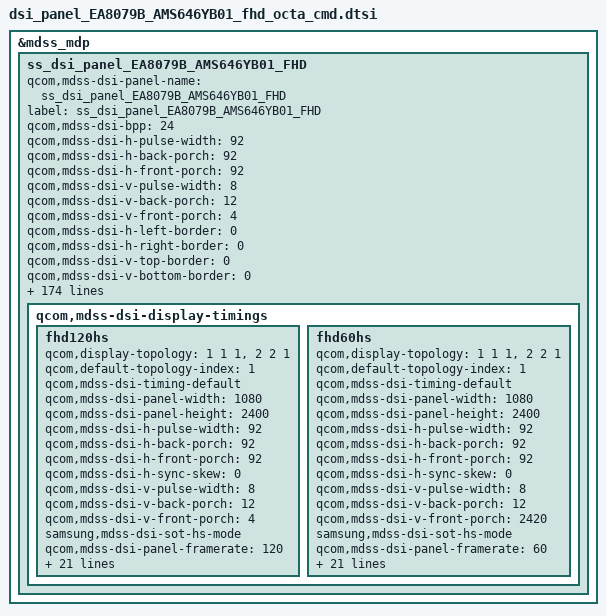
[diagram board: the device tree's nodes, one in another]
/* Copyright (c) 2020, Samsung Electronics Corporation. All rights reserved.
 *
 * This program is free software; you can redistribute it and/or modify
 * it under the terms of the GNU General Public License version 2 and
 * only version 2 as published by the Free Software Foundation.
 *
 * This program is distributed in the hope that it will be useful,
 * but WITHOUT ANY WARRANTY; without even the implied warranty of
 * MERCHANTABILITY or FITNESS FOR A PARTICULAR PURPOSE.  See the
 * GNU General Public License for more details.
 */

&mdss_mdp {
	ss_dsi_panel_EA8079B_AMS646YB01_FHD: ss_dsi_panel_EA8079B_AMS646YB01_FHD {
		qcom,mdss-dsi-panel-name = "ss_dsi_panel_EA8079B_AMS646YB01_FHD";
		label = "ss_dsi_panel_EA8079B_AMS646YB01_FHD";

		qcom,mdss-dsi-bpp = <24>;

		qcom,mdss-dsi-h-pulse-width = <92>;
		qcom,mdss-dsi-h-back-porch = <92>;
		qcom,mdss-dsi-h-front-porch = <92>;
		qcom,mdss-dsi-v-pulse-width = <8>;
		qcom,mdss-dsi-v-back-porch = <12>;
		qcom,mdss-dsi-v-front-porch = <4>;

		qcom,mdss-dsi-h-left-border = <0>;
		qcom,mdss-dsi-h-right-border = <0>;
		qcom,mdss-dsi-v-top-border = <0>;
		qcom,mdss-dsi-v-bottom-border = <0>;

		qcom,mdss-dsi-panel-phy-timings = [00 25 0A 0A 27 24 0A 0A 09 02 04 00 1F 1A];	// 1110 Mbps

		qcom,mdss-dsi-underflow-color = <0xFF>;
		qcom,mdss-dsi-border-color = <0>;

		qcom,mdss-dsi-bl-pmic-control-type = "bl_ctrl_dcs";

		qcom,mdss-dsi-bl-min-level = <1>;
		qcom,mdss-dsi-bl-max-level = <486>;
		qcom,mdss-brightness-max-level = <486>;
		qcom,mdss-brightness-default-level = <255>;
		qcom,mdss-dsi-interleave-mode = <0>;
		qcom,mdss-dsi-panel-type = "dsi_cmd_mode";

		qcom,mdss-dsi-te-check-enable;
		qcom,mdss-dsi-te-using-te-pin;
		qcom,mdss-dsi-te-pin-select = <1>;

		/*qcom,dynamic-mode-switch-enabled;*/
		/*qcom,dynamic-mode-switch-type = "dynamic-resolution-switch-immediate";*/

		qcom,mdss-dsi-te-dcs-command = <1>;
		qcom,mdss-dsi-wr-mem-start = <0x2C>;
		qcom,mdss-dsi-wr-mem-continue = <0x3C>;

		qcom,mdss-dsi-pixel-packing = "loose";

		qcom,mdss-dsi-virtual-channel-id = <0>;
		qcom,mdss-dsi-color-order = "rgb_swap_rgb";
		qcom,mdss-dsi-lane-0-state;
		qcom,mdss-dsi-lane-1-state;
		qcom,mdss-dsi-lane-2-state;
		qcom,mdss-dsi-lane-3-state;
		//qcom,mdss-dsi-lane-map = "lane_map_0123";

		qcom,mdss-dsi-t-clk-pre = <0x1F>;
		qcom,mdss-dsi-t-clk-post = <0x1A>;

		qcom,mdss-dsi-stream = <0>;
		qcom,mdss-dsi-mdp-trigger = "none";
		qcom,mdss-dsi-dma-trigger = "trigger_sw";

		qcom,mdss-pan-physical-width-dimension = <67>;	/*  67.28 : round-off */
		qcom,mdss-pan-physical-height-dimension = <150>;/* 149.52 : round-off */

		qcom,mdss-dsi-reset-sequence = <0 10>, <1 15>;

		qcom,mdss-dsi-lp11-init;
		/*qcom,mdss-dsi-init-delay-us = <1000>;*/

		qcom,mdss-dsi-rx-eot-ignore;
		qcom,mdss-dsi-tx-eot-append;

		/* HDR Setting */
		qcom,mdss-dsi-panel-hdr-enabled;
		qcom,mdss-dsi-panel-hdr-color-primaries = <15635 16450 34000 16000 13250 34500 7500 3000>;
		qcom,mdss-dsi-panel-peak-brightness = <5400000>;
		qcom,mdss-dsi-panel-average-brightness = <2000000>;
		qcom,mdss-dsi-panel-blackness-level = <2000>;

		qcom,ulps-enabled;
		/* qcom,suspend-ulps-enabled; */
		qcom,esd-check-enabled;
		qcom,mdss-dsi-panel-status-check-mode ="irq_check";
		qcom,mdss-dsi-panel-status-irq-trigger1 = "falling";
		/*qcom,mdss-dsi-panel-status-read-length;*/
		/*qcom,mdss-dsi-panel-status-value;*/
		/*qcom,mdss-dsi-panel-status-irq-trigger2 = "falling";*/

		/* *************************************************************
		 * Below  parameters are samsung dependent thigs
		 * *************************************************************
		 */
		samsung,panel-vendor = "SDC";
		samsung,disp-model = "AMS646YB01";
		samsung,panel-lpm-enable;
		samsung,support_gamma_mode2;
		//samsung,elvss_interpolation_temperature = <(-15)>;
		samsung,support_factory_panel_swap;
		samsung,support_gpara;
		samsung,pll_ssc_disabled;

		/* *************************************************************
		 *  Tx
		 * *************************************************************
		 */
		samsung,level0_key_enable_tx_cmds_revA	= [29 01 00 00 00 00 03 9F A5 A5]; /* PASSWD0 */
		samsung,level0_key_disable_tx_cmds_revA	= [29 01 00 00 00 00 03 9F 5A 5A]; /* PASSWD0 */
		samsung,level1_key_enable_tx_cmds_revA	= [29 01 00 00 00 00 03 F0 5A 5A]; /* PASSWD1 */
		samsung,level1_key_disable_tx_cmds_revA	= [29 01 00 00 00 00 03 F0 A5 A5]; /* PASSWD1 */
		samsung,level2_key_enable_tx_cmds_revA	= [29 01 00 00 00 00 03 FC 5A 5A];
		samsung,level2_key_disable_tx_cmds_revA	= [29 01 00 00 00 00 03 FC A5 A5];

		/* BRIGHTNESS_MAX_PACKET = 50 */
		samsung,brightness_tx_cmds_revA = [
			39 01 00 00 00 00 01 00
			39 01 00 00 00 00 01 00
			39 01 00 00 00 00 01 00
			39 01 00 00 00 00 01 00
			39 01 00 00 00 00 01 00
			39 01 00 00 00 00 01 00
			39 01 00 00 00 00 01 00
			39 01 00 00 00 00 01 00
			39 01 00 00 00 00 01 00
			39 01 00 00 00 00 01 00
			39 01 00 00 00 00 01 00
			39 01 00 00 00 00 01 00
			39 01 00 00 00 00 01 00
			39 01 00 00 00 00 01 00
			39 01 00 00 00 00 01 00
			39 01 00 00 00 00 01 00
			39 01 00 00 00 00 01 00
			39 01 00 00 00 00 01 00
			39 01 00 00 00 00 01 00
			39 01 00 00 00 00 01 00
			39 01 00 00 00 00 01 00
			39 01 00 00 00 00 01 00
			39 01 00 00 00 00 01 00
			39 01 00 00 00 00 01 00
			39 01 00 00 00 00 01 00
			39 01 00 00 00 00 01 00
			39 01 00 00 00 00 01 00
			39 01 00 00 00 00 01 00
			39 01 00 00 00 00 01 00
			39 01 00 00 00 00 01 00
			39 01 00 00 00 00 01 00
			39 01 00 00 00 00 01 00
			39 01 00 00 00 00 01 00
			39 01 00 00 00 00 01 00
			39 01 00 00 00 00 01 00
			39 01 00 00 00 00 01 00
			39 01 00 00 00 00 01 00
			39 01 00 00 00 00 01 00
			39 01 00 00 00 00 01 00
			39 01 00 00 00 00 01 00
			39 01 00 00 00 00 01 00
			39 01 00 00 00 00 01 00
			39 01 00 00 00 00 01 00
			39 01 00 00 00 00 01 00
			39 01 00 00 00 00 01 00
			39 01 00 00 00 00 01 00
			39 01 00 00 00 00 01 00
			39 01 00 00 00 00 01 00
			39 01 00 00 00 00 01 00
			39 01 00 00 00 00 01 00
		];

		//samsung,mdnie_tx_cmds_revA = [
		//	39 01 00 00 00 00 00 00 00
		//];

		samsung,packet_size_tx_cmds_revA = [
			37 01 00 00 00 00 02 07 00
		];

		/* use poinging gpara (long write) */
		samsung,reg_read_pos_tx_cmds_revA = [
			29 00 00 00 00 00 03 B0 00 00
		];

		samsung,display_on_tx_cmds_revA = [05 01 00 00 00 00 02 29 00];
		samsung,display_off_tx_cmds_revA = [05 01 00 00 00 00 02 28 00];

		/* *************************************************************
		 *  Rx (Module Information READ)
		 * *************************************************************
		 */
		samsung,mdnie_read_rx_cmds_revA		= [06 01 00 00 00 00 01 EA 04 03]; /* White color position EA 4th ~ 7th */
		samsung,manufacture_date_rx_cmds_revA	= [06 01 00 00 00 00 01 EA 07 07]; /* manufacture data EA 8th ~ 14th*/
		samsung,octa_id_rx_cmds_revA		= [06 01 00 00 00 00 01 EA 14 0E]; /* ID (4bytes) + Cell ID(16bytes) */
		samsung,cell_id_rx_cmds_revA		= [06 01 00 00 00 00 01 EA 07 07]; /* Cell ID 16bytes EA 8th ~ 14th*/
		samsung,ddi_id_rx_cmds_revA		= [06 01 00 00 00 00 01 D1 06 60]; /* CHIP ID : read D1 96~101th */
		samsung,ddi_id_length = <6>;

		samsung,manufacture_id0_rx_cmds_revA	= [06 01 00 00 00 00 01 da 01 00];
		samsung,manufacture_id1_rx_cmds_revA	= [06 01 00 00 00 00 01 db 01 00];
		samsung,manufacture_id2_rx_cmds_revA	= [06 01 00 00 00 00 01 dc 01 00];

		samsung,ldi_debug0_rx_cmds_revA		= [06 01 00 00 00 00 01 0A 01 00]; /* rddpm */
		//samsung,ldi_debug1_rx_cmds_revA		= [06 01 00 00 00 00 01 0E 01 00]; /* no operation */
		samsung,ldi_debug2_rx_cmds_revA		= [06 01 00 00 00 00 01 0E 01 00]; /* errfg */
		samsung,ldi_debug3_rx_cmds_revA		= [06 01 00 00 00 00 01 0E 01 00]; /* rddsm*/
		samsung,ldi_debug4_rx_cmds_revA		= [06 01 00 00 00 00 01 05 01 00]; /* dsierr */
		//samsung,ldi_debug5_rx_cmds_revA		= [06 01 00 00 00 00 01 0F 01 00]; /* self_diag*/

		/* 255 bytes, its ddi max size is 512, and sw limit is ff = 255... */
		//samsung,ldi_debug_logbuf_rx_cmds_revA	= [06 01 00 00 00 00 01 9C FF 00];

		samsung,mtp_read_sysfs_rx_cmds_revA	= [06 01 00 00 00 00 01 00 00 00];

		samsung,mtp_write_sysfs_tx_cmds_revA	= [
			29 00 00 00 00 00 3D 00
						00 00 00 00 00 00 00 00 00 00
						00 00 00 00 00 00 00 00 00 00
						00 00 00 00 00 00 00 00 00 00
						00 00 00 00 00 00 00 00 00 00
						00 00 00 00 00 00 00 00 00 00
						00 00 00 00 00 00 00 00 00 00
		];

		samsung,smart_dimming_mtp_rx_cmds_revA	= [06 01 00 00 00 00 01 B9 DE 00];

		/* *************************************************************
		 * ACL command list and mappings
		 * **************************************************************
		 */
		samsung,acl_on_tx_cmds_revA = [
			/* 32 frame AVG ACL ON, Start 50%, ACL 15%, 32Frame AVG */
			29 01 00 00 00 00 02 55 02	/* 8%(0x01), 15%(0x02) */
		];

		samsung,acl_off_tx_cmds_revA = [
			/* 16 Frame AVG ACL OFF, Start Point 60%, ACL 0%*/
			29 01 00 00 00 00 02 55 00	/* ACL OFF */
		];

		samsung,elvss_rx_cmds_revA = [ 06 01 00 00 00 00 01 B7 02 07];	/* read B7 8th, 9th para */

		/* *************************************************************
		 * Dynamic MIPI Clock
		 * **************************************************************
		 */
		samsung,support_dynamic_mipi_clk;
		samsung,ffc_cmds_line_position = <4>;
		samsung,ffc_tx_cmds_revA = [
			29 00 00 00 00 00 03 F0 5A 5A
			29 00 00 00 00 00 03 FC 5A 5A
			29 00 00 00 00 00 02 B0 01
			29 00 00 00 00 00 04 E4 A4 F5 BB
			29 00 00 00 00 00 0F E9 11 75 A4 F5 BB 9E 1F 46 9E 1F 46 00 32 32 /* 1110 Mbps (555) */
			29 01 00 00 00 00 03 F0 A5 A5
			29 01 00 00 00 00 03 FC A5 A5
		];

		samsung,ffc_off_tx_cmds_revA = [
			29 00 00 00 00 00 03 F0 5A 5A
			29 00 00 00 00 00 03 FC 5A 5A
			29 00 00 00 00 00 02 E9 10
			29 01 00 00 00 00 03 F0 A5 A5
			29 01 00 00 00 00 03 FC A5 A5
		];

		samsung,dyn_mipi_clk_ffc_cmds_pre_revA = [
			29 00 00 00 00 00 04 E4 A4 F5 BB /* 0 : 1110 Mbps (555) */
			29 00 00 00 00 00 04 E4 A4 F5 BB /* 1 : 1110 Mbps (555) */
			29 00 00 00 00 00 04 E4 A4 5E 19 /* 2 : 1114 Mbps (557) */
			29 00 00 00 00 00 04 E4 A2 E7 BD /* 3 : 1124 Mbps (562) */
		];

		samsung,dyn_mipi_clk_ffc_cmds_revA = [
			29 00 00 00 00 00 0F E9 11 75 A4 F5 BB 9E 1F 46 9E 1F 46 00 32 32 /* 0 : 1110 Mbps (555) */
			29 00 00 00 00 00 0F E9 11 75 A4 F5 BB 9E 1F 46 9E 1F 46 00 32 32 /* 1 : 1110 Mbps (555) */
			29 00 00 00 00 00 0F E9 11 75 A4 5E 19 9E 1F 46 9E 1F 46 00 32 32 /* 2 : 1114 Mbps (557) */
			29 00 00 00 00 00 0F E9 11 75 A2 E7 BD 9E 1F 46 9E 1F 46 00 32 32 /* 3 : 1124 Mbps (562) */
		];

		samsung,dynamic_mipi_clk_timing_table = <
			/*<bitclk><>*/
			1110000000 /* clk id 0 default */
			1110000000 /* clk id 1 A */
			1114000000 /* clk id 2 B */
			1124000000 /* clk id 3 C */
		>;

		samsung,dynamic_mipi_clk_sel_table = <
			/*<RAT><BAND><from><end><clk index>*/
                        1		1		0		0		1
                        1		2		0		0		1
                        1		3		0		0		3
                        1		4		0		0		2
                        2		11		10562		10838		1
                        2		12		9662		9677		1
                        2		12		9678		9712		2
                        2		12		9713		9747		3
                        2		12		9748		9938		1
                        2		13		1162		1178		3
                        2		13		1179		1513		1
                        2		14		1537		1738		1
                        2		15		4357		4458		1
                        2		17		2237		2271		1
                        2		17		2272		2318		2
                        2		17		2319		2341		3
                        2		17		2342		2563		1
                        2		18		2937		3088		1
                        3		91		0		599		1
                        3		92		600		654		1
                        3		92		655		724		2
                        3		92		725		794		3
                        3		92		795		1199		1
                        3		93		1200		1257		3
                        3		93		1258		1949		1
                        3		94		1950		2399		1
                        3		95		2400		2649		1
                        3		97		2750		2842		1
                        3		97		2843		2937		2
                        3		97		2938		2982		3
                        3		97		2983		3449		1
                        3		98		3450		3799		1
			3		102		5010		5179		1
			3		103		5180		5279		1
			3		104		5280		5379		1
                        3		107		5730		5849		1
                        3		108		5850		5999		1
                        3		109		6000		6149		1
                        3		110		6150		6449		1
                        3		111		6450		6599		1
                        3		115		8040		8094		1
                        3		115		8095		8164		2
                        3		115		8165		8234		3
                        3		115		8235		8689		1
                        3		116		8690		9039		1
                        3		118		9210		9659		1
                        3		119		9660		9769		1
                        3		120		9770		9787		1
                        3		120		9788		9869		2
                        3		122		9920		10359		1
                        3		124		36200		36349		1
                        3		128		37750		38249		1
                        3		129		38250		38649		1
                        3		130		38650		39167		1
                        3		130		39168		39252		2
                        3		130		39253		39307		3
                        3		130		39308		39649		1
                        3		131		39650		39684		2
                        3		131		39685		39734		3
                        3		131		39735		40982		1
                        3		131		40983		41077		2
                        3		131		41078		41122		3
                        3		131		41123		41589		1
                        3		132		41590		42207		1
                        3		132		42208		42332		2
                        3		132		42333		42347		3
                        3		132		42348		43589		1
                        3		138		55240		55745		1
                        3		138		55746		55875		2
                        3		138		55876		55885		3
                        3		138		55886		56739		1
                        3		156		66436		67335		1
                        3		161		68586		68935		1
                        4		51		0		0		1
                        4		52		0		0		1
                        4		53		0		0		1
                        4		54		0		0		1
                        4		55		0		0		3
                        4		56		0		0		1
                        5		61		0		0		1
                        5		62		0		0		1
                        5		71		0		0		1
                        7		260		173800		178780		1
                        7		263		185000		191840		1
                        7		263		191841		191980		2
                        7		283		151600		160580		1
                        7		326		123400		130380		1
		>;

		/* *************************************************************
		 * candela to index mappings
		 * **************************************************************
		 */
		//samsung,gamma_mode2_candela_map_table_revA = < /* THIS TABLE USED FOR DIMMING */
		samsung,candela_map_table_revA = < /* THIS TABLE USED FOR DIMMING */
		/* <idx> <from> <till> <gm2_wrdisbv> <cd> */
			0		0		0		3		2
			1		1		1		6		3
			2		2		2		10		5
			3		3		3		13		6
			4		4		4		17		8
			5		5		5		20		9
			6		6		6		24		11
			7		7		7		27		12
			8		8		8		31		13
			9		9		9		34		15
			10		10		10		38		16
			11		11		11		41		17
			12		12		12		45		19
			13		13		13		48		20
			14		14		14		52		22
			15		15		15		55		23
			16		16		16		59		25
			17		17		17		62		26
			18		18		18		66		28
			19		19		19		69		29
			20		20		20		73		30
			21		21		21		76		32
			22		22		22		79		33
			23		23		23		83		35
			24		24		24		86		36
			25		25		25		90		37
			26		26		26		93		39
			27		27		27		97		40
			28		28		28		100		41
			29		29		29		104		43
			30		30		30		107		44
			31		31		31		111		46
			32		32		32		114		47
			33		33		33		118		49
			34		34		34		121		50
			35		35		35		125		52
			36		36		36		128		53
			37		37		37		132		54
			38		38		38		135		56
			39		39		39		139		57
			40		40		40		142		59
			41		41		41		146		60
			42		42		42		149		61
			43		43		43		152		63
			44		44		44		156		64
			45		45		45		159		65
			46		46		46		163		67
			47		47		47		166		68
			48		48		48		170		70
			49		49		49		173		71
			50		50		50		177		73
			51		51		51		180		74
			52		52		52		184		76
			53		53		53		187		77
			54		54		54		191		78
			55		55		55		194		80
			56		56		56		198		81
			57		57		57		201		83
			58		58		58		205		84
			59		59		59		208		85
			60		60		60		212		87
			61		61		61		215		88
			62		62		62		219		90
			63		63		63		222		91
			64		64		64		225		92
			65		65		65		229		94
			66		66		66		232		95
			67		67		67		236		97
			68		68		68		239		98
			69		69		69		243		100
			70		70		70		246		101
			71		71		71		250		102
			72		72		72		253		104
			73		73		73		257		105
			74		74		74		260		107
			75		75		75		264		108
			76		76		76		267		109
			77		77		77		271		111
			78		78		78		274		112
			79		79		79		278		114
			80		80		80		281		115
			81		81		81		285		117
			82		82		82		288		118
			83		83		83		292		120
			84		84		84		295		121
			85		85		85		299		122
			86		86		86		302		124
			87		87		87		305		125
			88		88		88		309		126
			89		89		89		312		128
			90		90		90		316		129
			91		91		91		319		131
			92		92		92		323		132
			93		93		93		326		133
			94		94		94		330		135
			95		95		95		333		136
			96		96		96		337		138
			97		97		97		340		139
			98		98		98		344		141
			99		99		99		347		142
			100		100		100		351		144
			101		101		101		354		145
			102		102		102		358		146
			103		103		103		361		148
			104		104		104		365		149
			105		105		105		368		150
			106		106		106		372		152
			107		107		107		375		153
			108		108		108		378		155
			109		109		109		382		156
			110		110		110		385		157
			111		111		111		389		159
			112		112		112		392		160
			113		113		113		396		162
			114		114		114		399		163
			115		115		115		403		165
			116		116		116		406		166
			117		117		117		410		168
			118		118		118		413		169
			119		119		119		417		170
			120		120		120		420		172
			121		121		121		424		173
			122		122		122		427		174
			123		123		123		431		176
			124		124		124		434		177
			125		125		125		438		179
			126		126		126		441		180
			127		127		127		445		182
			128		128		128		448		183
			129		129		129		453		185
			130		130		130		457		187
			131		131		131		462		189
			132		132		132		466		190
			133		133		133		471		192
			134		134		134		475		194
			135		135		135		480		196
			136		136		136		484		198
			137		137		137		489		200
			138		138		138		493		202
			139		139		139		498		204
			140		140		140		502		205
			141		141		141		507		207
			142		142		142		511		209
			143		143		143		516		211
			144		144		144		520		213
			145		145		145		525		215
			146		146		146		529		216
			147		147		147		534		218
			148		148		148		539		221
			149		149		149		543		222
			150		150		150		548		224
			151		151		151		552		226
			152		152		152		557		228
			153		153		153		561		230
			154		154		154		566		232
			155		155		155		570		233
			156		156		156		575		235
			157		157		157		579		237
			158		158		158		584		239
			159		159		159		588		241
			160		160		160		593		243
			161		161		161		597		244
			162		162		162		602		246
			163		163		163		606		248
			164		164		164		611		250
			165		165		165		615		252
			166		166		166		620		254
			167		167		167		625		256
			168		168		168		629		258
			169		169		169		634		260
			170		170		170		638		261
			171		171		171		643		263
			172		172		172		647		265
			173		173		173		652		267
			174		174		174		656		269
			175		175		175		661		271
			176		176		176		665		272
			177		177		177		670		275
			178		178		178		674		276
			179		179		179		679		278
			180		180		180		683		280
			181		181		181		688		282
			182		182		182		692		284
			183		183		183		697		286
			184		184		184		702		288
			185		185		185		706		289
			186		186		186		711		291
			187		187		187		715		293
			188		188		188		720		295
			189		189		189		724		297
			190		190		190		729		299
			191		191		191		733		300
			192		192		192		738		303
			193		193		193		742		304
			194		194		194		747		306
			195		195		195		751		308
			196		196		196		756		310
			197		197		197		760		312
			198		198		198		765		314
			199		199		199		769		315
			200		200		200		774		317
			201		201		201		778		319
			202		202		202		783		321
			203		203		203		788		323
			204		204		204		792		325
			205		205		205		797		327
			206		206		206		801		328
			207		207		207		806		331
			208		208		208		810		332
			209		209		209		815		334
			210		210		210		819		336
			211		211		211		824		338
			212		212		212		828		340
			213		213		213		833		342
			214		214		214		837		343
			215		215		215		842		345
			216		216		216		846		347
			217		217		217		851		349
			218		218		218		855		351
			219		219		219		860		353
			220		220		220		865		355
			221		221		221		869		357
			222		222		222		874		359
			223		223		223		878		360
			224		224		224		883		362
			225		225		225		887		364
			226		226		226		892		366
			227		227		227		896		368
			228		228		228		901		370
			229		229		229		905		371
			230		230		230		910		373
			231		231		231		914		375
			232		232		232		919		377
			233		233		233		923		379
			234		234		234		928		381
			235		235		235		932		382
			236		236		236		937		385
			237		237		237		941		386
			238		238		238		946		388
			239		239		239		951		390
			240		240		240		955		392
			241		241		241		960		394
			242		242		242		964		396
			243		243		243		969		398
			244		244		244		973		399
			245		245		245		978		401
			246		246		246		982		403
			247		247		247		987		405
			248		248		248		991		407
			249		249		249		996		409
			250		250		250		1000		411
			251		251		251		1005		413
			252		252		252		1009		414
			253		253		253		1014		416
			254		254		254		1018		418
			255		255		255		1023		420
		>;

		samsung,hbm_candela_map_table_revA = <
		/* <idx> <from> <till> <gm2_wrdisbv> <cd> <auto> */
			0		256		256		0		427		0
			1		257		257		3		429		0
			2		258		258		5		430		0
			3		259		259		8		432		0
			4		260		260		11		434		0
			5		261		261		13		435		0
			6		262		262		16		437		0
			7		263		263		19		439		0
			8		264		264		21		440		0
			9		265		265		24		442		0
			10		266		266		27		443		0
			11		267		267		29		445		0
			12		268		268		32		446		0
			13		269		269		35		448		0
			14		270		270		37		450		0
			15		271		271		40		451		0
			16		272		272		43		453		0
			17		273		273		45		454		0
			18		274		274		48		456		0
			19		275		275		51		458		0
			20		276		276		53		459		0
			21		277		277		56		461		0
			22		278		278		59		463		0
			23		279		279		61		464		0
			24		280		280		64		466		0
			25		281		281		67		468		0
			26		282		282		69		469		0
			27		283		283		72		471		0
			28		284		284		75		473		0
			29		285		285		77		474		0
			30		286		286		80		476		0
			31		287		287		83		478		0
			32		288		288		85		479		0
			33		289		289		88		481		0
			34		290		290		91		482		0
			35		291		291		93		484		0
			36		292		292		96		485		0
			37		293		293		99		487		0
			38		294		294		101		488		0
			39		295		295		104		490		0
			40		296		296		107		492		0
			41		297		297		109		493		0
			42		298		298		112		495		0
			43		299		299		115		497		0
			44		300		300		117		498		0
			45		301		301		120		500		0
			46		302		302		123		502		0
			47		303		303		125		503		0
			48		304		304		128		505		0
			49		305		305		131		507		0
			50		306		306		133		508		0
			51		307		307		136		510		0
			52		308		308		139		512		0
			53		309		309		141		513		0
			54		310		310		144		515		0
			55		311		311		147		516		0
			56		312		312		149		518		0
			57		313		313		152		519		0
			58		314		314		155		521		0
			59		315		315		157		523		0
			60		316		316		160		524		0
			61		317		317		163		526		0
			62		318		318		165		527		0
			63		319		319		168		529		0
			64		320		320		171		531		0
			65		321		321		173		532		0
			66		322		322		176		534		0
			67		323		323		179		536		0
			68		324		324		181		537		0
			69		325		325		184		539		0
			70		326		326		187		541		0
			71		327		327		189		542		0
			72		328		328		192		544		0
			73		329		329		195		546		0
			74		330		330		197		547		0
			75		331		331		200		549		0
			76		332		332		203		551		0
			77		333		333		205		552		0
			78		334		334		208		554		0
			79		335		335		211		555		0
			80		336		336		213		557		0
			81		337		337		216		558		0
			82		338		338		219		560		0
			83		339		339		221		561		0
			84		340		340		224		563		0
			85		341		341		227		565		0
			86		342		342		229		566		0
			87		343		343		232		568		0
			88		344		344		235		570		0
			89		345		345		237		571		0
			90		346		346		240		573		0
			91		347		347		243		575		0
			92		348		348		245		576		0
			93		349		349		248		578		0
			94		350		350		251		580		0
			95		351		351		253		581		0
			96		352		352		256		583		0
			97		353		353		259		585		0
			98		354		354		261		586		0
			99		355		355		264		588		0
			100		356		356		267		589		0
			101		357		357		269		591		0
			102		358		358		272		593		0
			103		359		359		275		594		0
			104		360		360		277		596		0
			105		361		361		280		597		0
			106		362		362		283		599		0
			107		363		363		285		600		0
			108		364		364		288		602		0
			109		365		365		291		604		0
			110		366		366		293		605		0
			111		367		367		296		607		0
			112		368		368		298		608		0
			113		369		369		301		610		0
			114		370		370		304		612		0
			115		371		371		306		613		0
			116		372		372		309		615		0
			117		373		373		312		617		0
			118		374		374		314		618		0
			119		375		375		317		620		0
			120		376		376		320		622		0
			121		377		377		322		623		0
			122		378		378		325		625		0
			123		379		379		328		627		0
			124		380		380		330		628		0
			125		381		381		333		630		0
			126		382		382		336		631		0
			127		383		383		338		633		0
			128		384		384		341		634		0
			129		385		385		344		636		0
			130		386		386		346		638		0
			131		387		387		349		639		0
			132		388		388		352		641		0
			133		389		389		354		642		0
			134		390		390		357		644		0
			135		391		391		360		646		0
			136		392		392		362		647		0
			137		393		393		365		649		0
			138		394		394		368		651		0
			139		395		395		370		652		0
			140		396		396		373		654		0
			141		397		397		376		656		0
			142		398		398		378		657		0
			143		399		399		381		659		0
			144		400		400		384		661		0
			145		401		401		386		662		0
			146		402		402		389		664		0
			147		403		403		392		666		0
			148		404		404		394		667		0
			149		405		405		397		669		0
			150		406		406		400		670		0
			151		407		407		402		672		0
			152		408		408		405		673		0
			153		409		409		408		675		0
			154		410		410		410		676		0
			155		411		411		413		678		0
			156		412		412		416		680		0
			157		413		413		418		681		0
			158		414		414		421		683		0
			159		415		415		424		685		0
			160		416		416		426		686		0
			161		417		417		429		688		0
			162		418		418		432		690		0
			163		419		419		434		691		0
			164		420		420		437		693		0
			165		421		421		440		695		0
			166		422		422		442		696		0
			167		423		423		445		698		0
			168		424		424		448		700		0
			169		425		425		450		701		0
			170		426		426		453		703		0
			171		427		427		456		704		0
			172		428		428		458		706		0
			173		429		429		461		708		0
			174		430		430		464		709		0
			175		431		431		466		711		0
			176		432		432		469		712		0
			177		433		433		472		714		0
			178		434		434		474		715		0
			179		435		435		477		717		0
			180		436		436		480		719		0
			181		437		437		482		720		0
			182		438		438		485		722		0
			183		439		439		488		724		0
			184		440		440		490		725		0
			185		441		441		493		727		0
			186		442		442		496		729		0
			187		443		443		498		730		0
			188		444		444		501		732		0
			189		445		445		504		734		0
			190		446		446		506		735		0
			191		447		447		509		737		0
			192		448		448		512		739		0
			193		449		449		514		740		0
			194		450		450		517		742		0
			195		451		451		520		743		0
			196		452		452		522		745		0
			197		453		453		525		746		0
			198		454		454		528		748		0
			199		455		455		530		749		0
			200		456		456		533		751		0
			201		457		457		536		753		0
			202		458		458		538		754		0
			203		459		459		541		756		0
			204		460		460		544		758		0
			205		461		461		546		759		0
			206		462		462		549		761		0
			207		463		463		552		763		0
			208		464		464		554		764		0
			209		465		465		557		766		0
			210		466		466		560		768		0
			211		467		467		562		769		0
			212		468		468		565		771		0
			213		469		469		568		773		0
			214		470		470		570		774		0
			215		471		471		573		776		0
			216		472		472		576		777		0
			217		473		473		578		779		0
			218		474		474		581		781		0
			219		475		475		584		782		0
			220		476		476		586		784		0
			221		477		477		589		785		0
			222		478		478		592		787		0
			223		479		479		594		788		0
			224		480		480		597		790		0
			225		481		481		600		792		0
			226		482		482		602		793		0
			227		483		483		605		795		0
			228		484		484		608		797		0
			229		485		485		610		798		0
			230		486		486		613		800		0
		>;

		samsung,aod_candela_map_table_revA = <
		/* <idx> <from> <till> <gm2_wrdisbv> <cd> */
			0	0	5	0	2
			1	6	19	0	10
			2	20	40	0	30
			3	41	255	0	60
		>;

		samsung,gamma_mode2_normal_tx_cmds_revA=[
			39 00 00 00 00 00 02 60 10
			39 00 00 00 00 00 02 53 20
			39 00 00 00 00 00 07 B7 01 5C CB 0D C0 16
			39 01 00 00 00 00 03 51 03 FF
			39 00 00 00 00 00 02 B0 2D
			39 00 00 00 00 00 02 B7 19
		];

		samsung,gamma_mode2_hbm_tx_cmds_revA=[
			39 00 00 00 00 00 02 60 10
			39 00 00 00 00 00 02 53 E0
			39 00 00 00 00 00 07 B7 01 5C CB 0D C0 16
			39 01 00 00 00 00 03 51 03 FF
			39 00 00 00 00 00 02 B0 2D
			39 00 00 00 00 00 02 B7 19
		];

		/*
		 * ************************************************************************************************************************
		 *  FD Settings
		 * ************************************************************************************************************************
		 */

		samsung,fd_on_tx_cmds_revA = [
			29 00 00 00 00 00 03 F0 5A 5A
			29 00 00 00 00 00 02 B0 0A
			29 00 00 00 00 00 02 D5 01
			29 01 00 00 00 00 03 F0 A5 A5
		];

		samsung,fd_off_tx_cmds_revA = [
			29 00 00 00 00 00 03 F0 5A 5A
			29 00 00 00 00 00 02 B0 0A
			29 00 00 00 00 00 02 D5 02
			29 01 00 00 00 00 03 F0 A5 A5
		];

		/* *************************************************************
		 *   APLPM
		 * *************************************************************
		 */
		samsung,self_grid_on_revA = [
			/* TIG Enable */
			29 00 00 00 00 00 03 F0 5A 5A
			29 00 00 00 00 00 02 B0 08
			29 00 00 00 00 00 02 E6 81
			29 01 00 00 00 00 03 F0 A5 A5
		];

		samsung,self_grid_off_revA = [
			29 00 00 00 00 00 03 F0 5A 5A
			29 00 00 00 00 00 0F EC 00 00 00 C0 62 20 00 00 20 00 00 00 01 19
			29 01 00 00 15 00 03 F0 A5 A5

			/* TIG Disable */
			29 00 00 00 00 00 03 F0 5A 5A
			29 00 00 00 00 00 02 B0 08
			29 00 00 00 00 00 02 E6 01
			29 01 00 00 00 00 03 F0 A5 A5
		];

		samsung,lpm_on_tx_cmds_revA = [ // TX_LPM_ON
			/* Image write for HLPM/ALPM Mode */
			29 00 00 00 00 00 03 F0 5A 5A
			29 00 00 00 00 00 03 FC 5A 5A
			29 00 00 00 00 00 02 E3 00	/* HLPM Select : HLPM(00)/ALPM(01) */
			29 00 00 00 00 00 02 60 10      /* Freq setting */
			29 00 00 00 00 00 02 B0 0B	/* Global Para */
			29 00 00 00 00 00 03 BB 00 14	/* HLPM AOR Setting */
			29 00 00 00 00 00 02 B0 5F
			29 00 00 00 00 00 05 D3 3B 0F 3B 0F	/* HFP Setting */
			29 00 00 00 00 00 02 B0 78
			29 00 00 00 00 00 06 D3 32 00 00 03 32	/* HFP Setting */
			29 00 00 00 00 00 02 B0 04
			29 00 00 00 00 00 05 D9 48 44 45 4A	/* HFP Setting */
			29 00 00 00 00 00 02 B0 16
			29 00 00 00 00 00 03 D1 1B 10	/* HFP Setting */
			29 00 00 00 00 00 02 F7 03	/* Panel Update */
			29 00 00 00 01 00 02 53 23	/* HLPM On Setting */
			29 00 00 00 00 00 03 FC A5 A5
			29 01 00 00 11 00 03 F0 A5 A5
		];

		samsung,lpm_off_tx_cmds_revA = [
			/* Image write for Normal Mode */
			29 00 00 00 00 00 03 F0 5A 5A
			29 00 00 00 00 00 03 FC 5A 5A
			29 00 00 00 00 00 02 B0 5F
			29 00 00 00 00 00 05 D3 42 0F 42 0F             /* HFP Setting */
			29 00 00 00 00 00 02 B0 78
			29 00 00 00 00 00 06 D3 41 00 00 03 41		/* HFP Setting */
			29 00 00 00 00 00 02 B0 04
			29 00 00 00 00 00 05 D9 48 44 45 4A             /* HFP Setting */
			29 00 00 00 00 00 02 B0 16
			29 00 00 00 00 00 03 D1 1A 1E                   /* HFP Setting */
			29 00 00 00 00 00 02 F7 03                      /* Panel Update */
			29 00 00 00 00 00 03 51 00 00			/* 0nit Setting */
			29 00 00 00 22 00 02 53 20			/* ALPM/HLPM off  + 33.3 ms */
			29 00 00 00 00 00 02 60 10                      /* Freq Setting */
			29 00 00 00 00 00 07 B7 01 5C CB 0D C0 16	/* Elvss Return */
			29 00 00 00 00 00 03 FC A5 A5
			29 01 00 00 00 00 03 F0 A5 A5
		];

		/* ALPM/HLPM 2nit or 60nit On Commands */
		samsung,lpm_2nit_tx_cmds_revA  = [29 01 00 00 00 00 02 53 23];
		samsung,lpm_10nit_tx_cmds_revA = [29 01 00 00 00 00 02 53 23];
		samsung,lpm_30nit_tx_cmds_revA = [29 01 00 00 00 00 02 53 23];
		samsung,lpm_60nit_tx_cmds_revA = [29 01 00 00 00 00 02 53 23];

		/* HLPM / ALPM Control Commands */
		samsung,lpm_ctrl_hlpm_2nit_tx_cmds_revA  = [29 01 00 00 00 00 03 BB 09 24];
		samsung,lpm_ctrl_hlpm_10nit_tx_cmds_revA = [29 01 00 00 00 00 03 BB 08 00];
		samsung,lpm_ctrl_hlpm_30nit_tx_cmds_revA = [29 01 00 00 00 00 03 BB 04 F0];
		samsung,lpm_ctrl_hlpm_60nit_tx_cmds_revA = [29 01 00 00 00 00 03 BB 00 14];

		/* HLPM / ALPM brightness Commands: default HLPM 2nit */
		samsung,lpm_brightnes_tx_cmds_revA = [
			29 00 00 00 00 00 03 F0 5A 5A	/* TEST KEY Enable */
			29 00 00 00 00 00 02 B0 0B	/* Global Para */
			29 00 00 00 00 00 03 BB 09 24	/* HLPM AOR SETTING */
			29 00 00 00 01 00 02 53 23		/* HLPM On Setting */
			29 01 00 00 00 00 03 F0 A5 A5	/* TEST KEY Disable */
		];

		/* *************************************************************
		 *  VRR
		 * **************************************************************
		 */
		samsung,vrr_gm2_gamma_comp_tx_cmds_revA = [
			29 00 00 00 00 00 02 B0 81	/* Global Para */
			29 01 00 00 00 00 73 B7		/* B7 : 0x81(129) ~ 0xF2(242) ==> 114(0x72) */
					00 00 00 00 00 00 00 00 00 00
					00 00 00 00 00 00 00 00 00 00
					00 00 00 00 00 00 00 00 00 00
					00 00 00 00 00 00 00 00 00 00
					00 00 00 00 00 00 00 00 00 00
					00 00 00 00 00 00 00 00 00 00
					00 00 00 00 00 00 00 00 00 00
					00 00 00 00 00 00 00 00 00 00
					00 00 00 00 00 00 00 00 00 00
					00 00 00 00 00 00 00 00 00 00
					00 00 00 00 00 00 00 00 00 00
					00 00 00 00
			29 01 00 00 00 00 91 B8		/* B8 : 0x00(0) ~ 0x8F(143) ==> 144(0x90) */
					00 00 00 00 00 00 00 00 00 00
					00 00 00 00 00 00 00 00 00 00
					00 00 00 00 00 00 00 00 00 00
					00 00 00 00 00 00 00 00 00 00
					00 00 00 00 00 00 00 00 00 00
					00 00 00 00 00 00 00 00 00 00
					00 00 00 00 00 00 00 00 00 00
					00 00 00 00 00 00 00 00 00 00
					00 00 00 00 00 00 00 00 00 00
					00 00 00 00 00 00 00 00 00 00
					00 00 00 00 00 00 00 00 00 00
					00 00 00 00 00 00 00 00 00 00
					00 00 00 00 00 00 00 00 00 00
					00 00 00 00 00 00 00 00 00 00
					00 00 00 00
		];

		samsung,vrr_tx_cmds_revA = [
			29 00 00 00 00 00 03 F0 5A 5A
			29 00 00 00 00 00 02 60 10		// 120 Hz    : 0x10
			29 00 00 00 00 00 02 B0 0B
			29 00 00 00 00 00 03 D8 A9 70		// 120/60 Hz : 0xA9 0x70
			29 00 00 00 00 00 02 B0 D4
			29 00 00 00 00 00 19 BA 		// 120/60 Hz : Blur Setting
				12 E0 09 2E 09 03 08 96
				08 2C 07 52 06 42 05 2A
				03 DA 02 82 01 2C 00 14
			29 00 00 00 00 00 08 BB 7A 01 25 00 14 20 30	// 120/60 Hz Porch Setting (0x20)
			29 00 00 00 00 00 02 F7 03
			29 01 00 00 00 00 03 F0 A5 A5
		];

		samsung,support_vrr_based_bl; /* VRR Variable Refresh Rate */

		/*
		* ************************************************************************************************************************
		*  DMS (Dynamic Mode Switch)
		* ************************************************************************************************************************
		*/

		qcom,mdss-dsi-display-timings {
			fhd120hs {
				qcom,display-topology = <1 1 1>, <2 2 1>; // lm, enc, intf
				qcom,default-topology-index = <1>;
				qcom,mdss-dsi-timing-default;
				qcom,mdss-dsi-panel-width = <1080>;
				qcom,mdss-dsi-panel-height = <2400>;

				qcom,mdss-dsi-h-pulse-width = <92>;
				qcom,mdss-dsi-h-back-porch = <92>;
				qcom,mdss-dsi-h-front-porch = <92>;
				qcom,mdss-dsi-h-sync-skew = <0>;

				qcom,mdss-dsi-v-pulse-width = <8>;
				qcom,mdss-dsi-v-back-porch = <12>;
				qcom,mdss-dsi-v-front-porch = <4>;

				samsung,mdss-dsi-sot-hs-mode; // HS Setting
				qcom,mdss-dsi-panel-framerate = <120>;
				qcom,mdss-mdp-transfer-time-us = <7533>; /* transfer time: 48Hz: 20032, 60Hz: 15866, 96Hz: 9616, 120Hz: 7533 */

				qcom,mdss-dsi-panel-clockrate = <1110000000>; /* 1110 Mbps*/
				qcom,mdss-dsi-panel-phy-timings = [00 25 0A 0A 27 24 0A 0A 09 02 04 00 1F 1A];	// 1110 Mbps

				/*qcom,mdss-dsi-timing-switch-command; use samsung,panel_multires_XXX instead*/
				/*qcom,mdss-dsi-timing-switch-command-state;*/
				//qcom,mdss-dsi-timing-switch-command = [ /* Freq Setting: 120Hz */
				//	39 01 00 00 00 00 02 60 10
				//];

				qcom,mdss-dsi-t-clk-pre = <0x1F>;
				qcom,mdss-dsi-t-clk-post = <0x1A>;

				qcom,mdss-dsi-on-command = [
					/* Sleep out, wait 10ms(0x0A) */
					05 01 00 00 0A 00 02 11 00

					/* TE Vsync On */
					29 00 00 00 00 00 03 F0 5A 5A
					29 00 00 00 00 00 02 35 00
					29 01 00 00 00 00 03 F0 A5 A5

					/* PAGE Address Setting */
					29 00 00 00 00 00 05 2A 00 00 04 37
					29 01 00 00 00 00 05 2B 00 00 09 5F

					/* Vsync Setting */
					29 00 00 00 00 00 03 F0 5A 5A
					29 00 00 00 00 00 02 B0 01
					29 00 00 00 00 00 02 E6 01
					29 01 00 00 00 00 03 F0 A5 A5

					/* PCD Setting */
					29 00 00 00 00 00 03 F0 5A 5A
					29 00 00 00 00 00 03 E8 55 12 // Default Low(55) / Disable SW Reset (12)
					29 01 00 00 00 00 03 F0 A5 A5

					/* ACL Setting Value */
					29 00 00 00 00 00 03 F0 5A 5A
					29 00 00 00 00 00 02 B0 CA
					29 00 00 00 00 00 02 BB 0B
					29 00 00 00 00 00 02 B0 CF
					29 00 00 00 00 00 03 BB 41 FF
					29 00 00 00 00 00 02 B0 D9
					29 00 00 00 00 00 02 BB 20
					29 01 00 00 00 00 03 F0 A5 A5

					/* DSC Setting */
					29 01 00 00 00 00 03 F0 5A 5A
					07 01 00 00 00 00 01 01               /* Compression Enable */
					0A 01 00 00 00 00 80                  /* PPS setting */
						11 00 00 89 30 80 09
						60 04 38 00 28 02 1C
						02 1C 02 00 02 0E 00
						20 03 DD 00 07 00 0C
						02 77 02 8B 18 00 10
						F0 03 0C 20 00 06 0B
						0B 33 0E 1C 2A 38 46
						54 62 69 70 77 79 7B
						7D 7E 01 02 01 00 09
						40 09 BE 19 FC 19 FA
						19 F8 1A 38 1A 78 1A
						B6 2A F6 2B 34 2B 74
						3B 74 6B F4 00 00 00
						00 00 00 00 00 00 00
						00 00 00 00 00 00 00
						00 00 00 00 00 00 00
						00 00 00 00 00 00 00
						00 00 00 00 00 00 00
						00 00
					29 01 00 00 00 00 03 F0 A5 A5

					/* TE Setting */
					29 00 00 00 00 00 03 F0 5A 5A
					29 00 00 00 00 00 08 DF 00 00 00 01 95 80 0C
					29 01 00 00 00 00 03 F0 A5 A5

					/* Smooth Dimming Setting */
					29 00 00 00 00 00 03 F0 5A 5A
					29 00 00 00 00 00 02 B0 06
					29 00 00 00 00 00 02 B7 08
					29 01 00 00 00 00 03 F0 A5 A5

					/* AOD Setting */
					29 00 00 00 00 00 03 F0 5A 5A
					29 00 00 00 00 00 02 B0 09
					29 00 00 00 00 00 02 EE 00
					29 01 00 00 00 00 03 F0 A5 A5

					/* SAP Setting */
					29 00 00 00 00 00 03 F0 5A 5A
					29 00 00 00 00 00 02 B0 03
					29 00 00 00 00 00 03 D4 10 10
					29 00 00 00 00 00 02 F7 03
					29 01 00 00 00 00 03 F0 A5 A5

					/* Brightness */
					29 00 00 00 00 00 03 F0 5A 5A
					29 00 00 00 00 00 02 60 10		/* 0x10 : 120 Hz */
					29 00 00 00 00 00 02 53 20		/* Dimming Speed */
					29 00 00 00 00 00 07 B7 01 5C CB 0D C0 16	/* ELVSS */
					29 01 00 00 00 00 03 51 03 FF		/* 420 nit */
					29 01 00 00 6E 00 03 F0 A5 A5
					/* Wait 110ms(0x6E) */
				];

				qcom,mdss-dsi-off-command=[
					05 01 00 00 14 00 02 28 00	/* wait 20ms(0x14) */
					05 01 00 00 78 00 02 10 00
				];

				qcom,mdss-dsi-on-command-state = "dsi_hs_mode"; /* Magna DSC command only works in HS. */
				qcom,mdss-dsi-off-command-state = "dsi_hs_mode";

				qcom,compression-mode = "dsc";
				qcom,lm-split = <540 540>;
				qcom,mdss-dsc-encoders = <2>;
				qcom,mdss-dsc-slice-height = <40>;
				qcom,mdss-dsc-slice-width = <540>;
				qcom,mdss-dsc-slice-per-pkt = <1>;
				qcom,mdss-dsc-bit-per-component = <8>;
				qcom,mdss-dsc-bit-per-pixel = <8>;
				qcom,mdss-dsc-block-prediction-enable;
			};

			fhd60hs {
				qcom,display-topology = <1 1 1>, <2 2 1>;
				qcom,default-topology-index = <1>;
				qcom,mdss-dsi-timing-default;
				qcom,mdss-dsi-panel-width = <1080>;
				qcom,mdss-dsi-panel-height = <2400>;

				qcom,mdss-dsi-h-pulse-width = <92>;
				qcom,mdss-dsi-h-back-porch = <92>;
				qcom,mdss-dsi-h-front-porch = <92>;
				qcom,mdss-dsi-h-sync-skew = <0>;

				qcom,mdss-dsi-v-pulse-width = <8>;
				qcom,mdss-dsi-v-back-porch = <12>;
				qcom,mdss-dsi-v-front-porch = <2420>;

				samsung,mdss-dsi-sot-hs-mode; // HS Setting
				qcom,mdss-dsi-panel-framerate = <60>;
				qcom,mdss-mdp-transfer-time-us = <15866>; /* transfer time: 48Hz: 20032, 60Hz: 15866, 96Hz: 9616, 120Hz: 7533 */
				qcom,mdss-dsi-panel-clockrate = <1110000000>; /* 1110 Mbps*/
				qcom,mdss-dsi-panel-phy-timings = [00 25 0A 0A 27 24 0A 0A 09 02 04 00 1F 1A];	// 1110 Mbps

				qcom,mdss-dsi-t-clk-pre = <0x1F>;
				qcom,mdss-dsi-t-clk-post = <0x1A>;

				qcom,mdss-dsi-on-command = [
					/* Sleep out, wait 10ms(0x0A) */
					05 01 00 00 0A 00 02 11 00

					/* TE Vsync On */
					29 00 00 00 00 00 03 F0 5A 5A
					29 00 00 00 00 00 02 35 00
					29 01 00 00 00 00 03 F0 A5 A5

					/* PAGE Address Setting */
					29 00 00 00 00 00 05 2A 00 00 04 37
					29 01 00 00 00 00 05 2B 00 00 09 5F

					/* Vsync Setting */
					29 00 00 00 00 00 03 F0 5A 5A
					29 00 00 00 00 00 02 B0 01
					29 00 00 00 00 00 02 E6 01
					29 01 00 00 00 00 03 F0 A5 A5

					/* PCD Setting */
					29 00 00 00 00 00 03 F0 5A 5A
					29 00 00 00 00 00 03 E8 55 12 // Default Low(55) / Disable SW Reset (12)
					29 01 00 00 00 00 03 F0 A5 A5

					/* ACL Setting Value */
					29 00 00 00 00 00 03 F0 5A 5A
					29 00 00 00 00 00 02 B0 CA
					29 00 00 00 00 00 02 BB 0B
					29 00 00 00 00 00 02 B0 CF
					29 00 00 00 00 00 03 BB 41 FF
					29 00 00 00 00 00 02 B0 D9
					29 00 00 00 00 00 02 BB 20
					29 01 00 00 00 00 03 F0 A5 A5

					/* DSC Setting */
					29 01 00 00 00 00 03 F0 5A 5A
					07 01 00 00 00 00 01 01               /* Compression Enable */
					0A 01 00 00 00 00 80                  /* PPS setting */
						11 00 00 89 30 80 09
						60 04 38 00 28 02 1C
						02 1C 02 00 02 0E 00
						20 03 DD 00 07 00 0C
						02 77 02 8B 18 00 10
						F0 03 0C 20 00 06 0B
						0B 33 0E 1C 2A 38 46
						54 62 69 70 77 79 7B
						7D 7E 01 02 01 00 09
						40 09 BE 19 FC 19 FA
						19 F8 1A 38 1A 78 1A
						B6 2A F6 2B 34 2B 74
						3B 74 6B F4 00 00 00
						00 00 00 00 00 00 00
						00 00 00 00 00 00 00
						00 00 00 00 00 00 00
						00 00 00 00 00 00 00
						00 00 00 00 00 00 00
						00 00
					29 01 00 00 00 00 03 F0 A5 A5

					/* A-sync Setting */
					29 01 00 00 00 00 03 F0 5A 5A
					29 00 00 00 00 00 02 60 00		//0x00 : 96/60/48 Hz
					29 00 00 00 00 00 02 B0 0B
					29 00 00 00 00 00 03 D8 A9 70		//0xA9 0x70 : 120/60 Hz
					29 00 00 00 00 00 02 B0 D4
					29 00 00 00 00 00 19 BA			//120/60 Hz Blur Setting
						12 E0 09 2E 09 03 08 96
						08 2C 07 52 06 42 05 2A
						03 DA 02 82 01 2C 00 14
					29 00 00 00 00 00 08 BB 7A 01 25 00 14 20 30 //0x20:120/60 Hz Porch Setting
					29 00 00 00 00 00 02 F7 03
					29 01 00 00 00 00 03 F0 A5 A5

					/* TE Setting */
					29 00 00 00 00 00 03 F0 5A 5A
					29 00 00 00 00 00 08 DF 00 00 00 01 95 80 0C
					29 01 00 00 00 00 03 F0 A5 A5

					/* Smooth Dimming Setting */
					29 00 00 00 00 00 03 F0 5A 5A
					29 00 00 00 00 00 02 B0 06
					29 00 00 00 00 00 02 B7 08
					29 01 00 00 00 00 03 F0 A5 A5

					/* AOD Setting */
					29 00 00 00 00 00 03 F0 5A 5A
					29 00 00 00 00 00 02 B0 09
					29 00 00 00 00 00 02 EE 00
					29 01 00 00 00 00 03 F0 A5 A5

					/* SAP Setting */
					29 00 00 00 00 00 03 F0 5A 5A
					29 00 00 00 00 00 02 B0 03
					29 00 00 00 00 00 03 D4 10 10
					29 00 00 00 00 00 02 F7 03
					29 01 00 00 00 00 03 F0 A5 A5

					/* Brightness */
					29 00 00 00 00 00 03 F0 5A 5A
					29 00 00 00 00 00 02 60 00		/* 0x00 : 60 Hz */
					29 00 00 00 00 00 02 53 20		/* Dimming Speed */
					29 00 00 00 00 00 07 B7 01 5C CB 0D C0 16	/* ELVSS */
					29 01 00 00 00 00 03 51 03 FF	/* 420 nit */
					29 01 00 00 6E 00 03 F0 A5 A5
					/* Wait 110ms(0x6E) */
				];

				qcom,mdss-dsi-off-command=[
					05 01 00 00 14 00 02 28 00	/* wait 20ms(0x14) */
					05 01 00 00 78 00 02 10 00
				];

				qcom,mdss-dsi-on-command-state = "dsi_hs_mode";  /* Magna DSC command only works in HS. */
				qcom,mdss-dsi-off-command-state = "dsi_hs_mode";

				qcom,compression-mode = "dsc";
				qcom,lm-split = <540 540>;
				qcom,mdss-dsc-encoders = <2>;
				qcom,mdss-dsc-slice-height = <40>;
				qcom,mdss-dsc-slice-width = <540>;
				qcom,mdss-dsc-slice-per-pkt = <1>;
				qcom,mdss-dsc-bit-per-component = <8>;
				qcom,mdss-dsc-bit-per-pixel = <8>;
				qcom,mdss-dsc-block-prediction-enable;
			};
		};
	};
};
